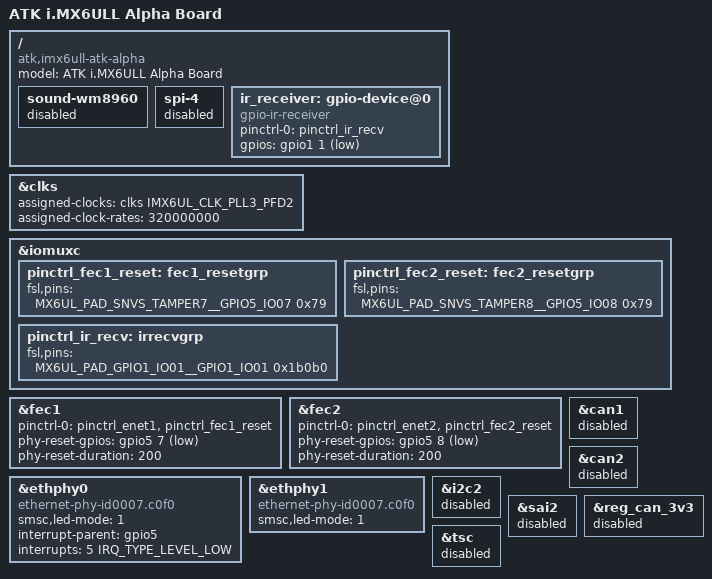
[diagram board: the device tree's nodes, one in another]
// SPDX-License-Identifier: (GPL-2.0 OR MIT)
//
// Board-specific device tree for the ATK Alpha hardware.

/dts-v1/;

#include "nxp/imx/imx6ull.dtsi"
#include "nxp/imx/imx6ul-14x14-evk.dtsi"

/ {
	model = "ATK i.MX6ULL Alpha Board";
	compatible = "atk,imx6ull-atk-alpha", "fsl,imx6ull";

	sound-wm8960 {
		status = "disabled";
	};

	spi-4 {
		status = "disabled";
	};

	ir_receiver: gpio-device@0 {
		compatible = "gpio-ir-receiver";
		pinctrl-names = "default";
		pinctrl-0 = <&pinctrl_ir_recv>;
		gpios = <&gpio1 1 GPIO_ACTIVE_LOW>;
		status = "okay";
	};
};

&clks {
	assigned-clocks = <&clks IMX6UL_CLK_PLL3_PFD2>;
	assigned-clock-rates = <320000000>;
};

&iomuxc {
	pinctrl_fec1_reset: fec1_resetgrp {
		fsl,pins = <
			MX6UL_PAD_SNVS_TAMPER7__GPIO5_IO07	0x79
		>;
	};

	pinctrl_fec2_reset: fec2_resetgrp {
		fsl,pins = <
			MX6UL_PAD_SNVS_TAMPER8__GPIO5_IO08	0x79
		>;
	};

	pinctrl_ir_recv: irrecvgrp {
		fsl,pins = <
			MX6UL_PAD_GPIO1_IO01__GPIO1_IO01	0x1b0b0
		>;
	};
};

&fec1 {
	pinctrl-0 = <&pinctrl_enet1 &pinctrl_fec1_reset>;
	phy-reset-gpios = <&gpio5 7 GPIO_ACTIVE_LOW>;
	phy-reset-duration = <200>;
	status = "okay";
};

&fec2 {
	pinctrl-0 = <&pinctrl_enet2 &pinctrl_fec2_reset>;
	phy-reset-gpios = <&gpio5 8 GPIO_ACTIVE_LOW>;
	phy-reset-duration = <200>;
	status = "okay";
};

&ethphy0 {
	compatible = "ethernet-phy-id0007.c0f0";
	smsc,led-mode = <1>;

	/* ENET1_INT_TREE# -> J2_10 -> SNVS_TAMPER5 -> GPIO5_IO05. */
	interrupt-parent = <&gpio5>;
	interrupts = <5 IRQ_TYPE_LEVEL_LOW>;
};

&ethphy1 {
	compatible = "ethernet-phy-id0007.c0f0";
	smsc,led-mode = <1>;
};

&can1 {
	status = "disabled";
};

&can2 {
	status = "disabled";
};

&i2c2 {
	status = "disabled";
};

&sai2 {
	status = "disabled";
};

&reg_can_3v3 {
	status = "disabled";
};

&tsc {
	status = "disabled";
};
